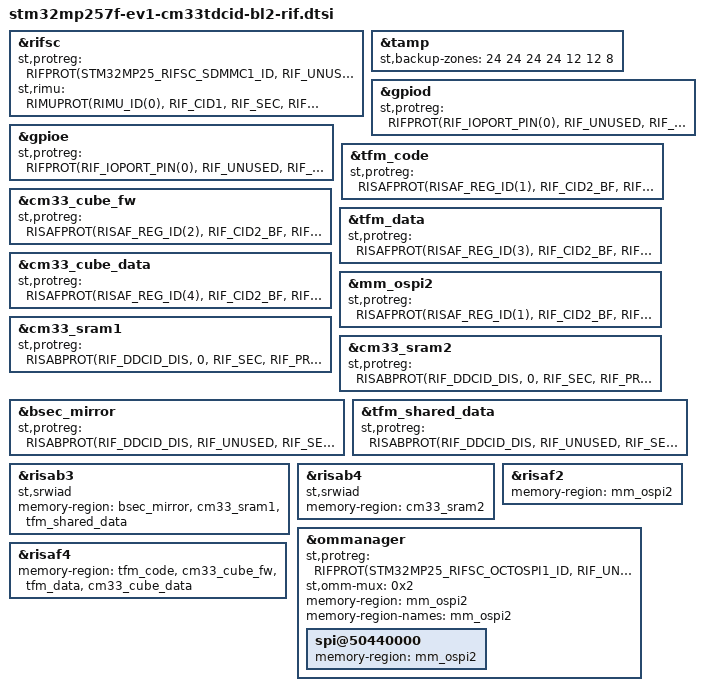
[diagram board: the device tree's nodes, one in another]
// SPDX-License-Identifier: (BSD-3-Clause)
/*
 * Copyright (C) STMicroelectronics 2023 - All Rights Reserved
 */
#include <dt-bindings/rif/stm32mp25-rif.h>
#include <dt-bindings/rif/stm32mp25-rifsc.h>
#include <dt-bindings/rif/stm32mp25-risaf.h>
#include <dt-bindings/rif/stm32mp25-risab.h>

&rifsc {
	status = "okay";

	st,protreg = <
		RIFPROT(STM32MP25_RIFSC_SDMMC1_ID, RIF_UNUSED, RIF_UNLOCK, RIF_SEC, RIF_PRIV, RIF_CID2, RIF_SEM_DIS, RIF_CFEN)
		RIFPROT(STM32MP25_RIFSC_SDMMC2_ID, RIF_UNUSED, RIF_UNLOCK, RIF_SEC, RIF_PRIV, RIF_CID2, RIF_SEM_DIS, RIF_CFEN)
	>;
	st,rimu = <
		RIMUPROT(RIMU_ID(0), RIF_CID1, RIF_SEC, RIF_PRIV, RIF_CIDSEL_P)
		RIMUPROT(RIMU_ID(1), RIF_UNUSED, RIF_SEC, RIF_PRIV, RIF_CIDSEL_P)
		RIMUPROT(RIMU_ID(2), RIF_UNUSED, RIF_SEC, RIF_PRIV, RIF_CIDSEL_P)
		RIMUPROT(RIMU_ID(3), RIF_CID0, RIF_NSEC, RIF_NPRIV, RIF_CIDSEL_P)
		RIMUPROT(RIMU_ID(4), RIF_CID0, RIF_NSEC, RIF_NPRIV, RIF_CIDSEL_P)
		RIMUPROT(RIMU_ID(5), RIF_CID0, RIF_NSEC, RIF_NPRIV, RIF_CIDSEL_P)
		RIMUPROT(RIMU_ID(6), RIF_CID0, RIF_NSEC, RIF_NPRIV, RIF_CIDSEL_P)
		RIMUPROT(RIMU_ID(7), RIF_CID0, RIF_NSEC, RIF_NPRIV, RIF_CIDSEL_P)
		RIMUPROT(RIMU_ID(8), RIF_CID1, RIF_NSEC, RIF_NPRIV, RIF_CIDSEL_P)
		RIMUPROT(RIMU_ID(9), RIF_CID1, RIF_NSEC, RIF_NPRIV, RIF_CIDSEL_P)
		RIMUPROT(RIMU_ID(10), RIF_CID0, RIF_NSEC, RIF_NPRIV, RIF_CIDSEL_P)
		RIMUPROT(RIMU_ID(11), RIF_CID0, RIF_NSEC, RIF_NPRIV, RIF_CIDSEL_M)
		RIMUPROT(RIMU_ID(12), RIF_CID0, RIF_NSEC, RIF_NPRIV, RIF_CIDSEL_M)
		RIMUPROT(RIMU_ID(13), RIF_CID0, RIF_NSEC, RIF_NPRIV, RIF_CIDSEL_M)
		RIMUPROT(RIMU_ID(14), RIF_CID0, RIF_NSEC, RIF_NPRIV, RIF_CIDSEL_P)
		RIMUPROT(RIMU_ID(15), RIF_CID0, RIF_NSEC, RIF_NPRIV, RIF_CIDSEL_P)
	>;
};

&tamp {
	st,backup-zones = <24 24 24 24 12 12 8>;
};

&gpiod {
	st,protreg = <
		RIFPROT(RIF_IOPORT_PIN(0), RIF_UNUSED, RIF_UNLOCK, RIF_SEC, RIF_PRIV, RIF_CID2, RIF_SEM_DIS, RIF_CFEN)
		RIFPROT(RIF_IOPORT_PIN(1), RIF_UNUSED, RIF_UNLOCK, RIF_SEC, RIF_NPRIV, RIF_CID1, RIF_SEM_DIS, RIF_CFEN)
		RIFPROT(RIF_IOPORT_PIN(2), RIF_UNUSED, RIF_UNLOCK, RIF_SEC, RIF_PRIV, RIF_CID1, RIF_SEM_DIS, RIF_CFEN)
		RIFPROT(RIF_IOPORT_PIN(3), RIF_UNUSED, RIF_UNLOCK, RIF_SEC, RIF_PRIV, RIF_CID2, RIF_SEM_DIS, RIF_CFEN)
		RIFPROT(RIF_IOPORT_PIN(4), RIF_UNUSED, RIF_UNLOCK, RIF_SEC, RIF_PRIV, RIF_CID2, RIF_SEM_DIS, RIF_CFEN)
		RIFPROT(RIF_IOPORT_PIN(5), RIF_UNUSED, RIF_UNLOCK, RIF_SEC, RIF_PRIV, RIF_CID2, RIF_SEM_DIS, RIF_CFEN)
		RIFPROT(RIF_IOPORT_PIN(6), RIF_UNUSED, RIF_UNLOCK, RIF_SEC, RIF_PRIV, RIF_CID2, RIF_SEM_DIS, RIF_CFEN)
		RIFPROT(RIF_IOPORT_PIN(7), RIF_UNUSED, RIF_UNLOCK, RIF_SEC, RIF_PRIV, RIF_CID2, RIF_SEM_DIS, RIF_CFEN)
		RIFPROT(RIF_IOPORT_PIN(8), RIF_UNUSED, RIF_UNLOCK, RIF_SEC, RIF_PRIV, RIF_CID1, RIF_SEM_DIS, RIF_CFEN)
		RIFPROT(RIF_IOPORT_PIN(9), RIF_UNUSED, RIF_UNLOCK, RIF_SEC, RIF_PRIV, RIF_CID1, RIF_SEM_DIS, RIF_CFEN)
		RIFPROT(RIF_IOPORT_PIN(10), RIF_UNUSED, RIF_UNLOCK, RIF_SEC, RIF_NPRIV, RIF_CID1, RIF_SEM_DIS, RIF_CFEN)
		RIFPROT(RIF_IOPORT_PIN(11), RIF_UNUSED, RIF_UNLOCK, RIF_SEC, RIF_NPRIV, RIF_CID1, RIF_SEM_DIS, RIF_CFEN)
		RIFPROT(RIF_IOPORT_PIN(12), RIF_UNUSED, RIF_UNLOCK, RIF_NSEC, RIF_NPRIV, RIF_UNUSED, RIF_SEM_DIS, RIF_CFDIS)
		RIFPROT(RIF_IOPORT_PIN(13), RIF_UNUSED, RIF_UNLOCK, RIF_NSEC, RIF_NPRIV, RIF_UNUSED, RIF_SEM_DIS, RIF_CFDIS)
		RIFPROT(RIF_IOPORT_PIN(14), RIF_UNUSED, RIF_UNLOCK, RIF_NSEC, RIF_NPRIV, RIF_UNUSED, RIF_SEM_DIS, RIF_CFDIS)
		RIFPROT(RIF_IOPORT_PIN(15), RIF_UNUSED, RIF_UNLOCK, RIF_NSEC, RIF_NPRIV, RIF_UNUSED, RIF_SEM_DIS, RIF_CFDIS)
	>;
};

&gpioe {
	st,protreg = <
		RIFPROT(RIF_IOPORT_PIN(0), RIF_UNUSED, RIF_UNLOCK, RIF_SEC, RIF_PRIV, RIF_CID2, RIF_SEM_DIS, RIF_CFEN)
		RIFPROT(RIF_IOPORT_PIN(1), RIF_UNUSED, RIF_UNLOCK, RIF_SEC, RIF_PRIV, RIF_CID2, RIF_SEM_DIS, RIF_CFEN)
		RIFPROT(RIF_IOPORT_PIN(2), RIF_UNUSED, RIF_UNLOCK, RIF_SEC, RIF_PRIV, RIF_CID2, RIF_SEM_DIS, RIF_CFEN)
		RIFPROT(RIF_IOPORT_PIN(3), RIF_UNUSED, RIF_UNLOCK, RIF_SEC, RIF_PRIV, RIF_CID2, RIF_SEM_DIS, RIF_CFEN)
		RIFPROT(RIF_IOPORT_PIN(4), RIF_UNUSED, RIF_UNLOCK, RIF_SEC, RIF_PRIV, RIF_CID2, RIF_SEM_DIS, RIF_CFEN)
		RIFPROT(RIF_IOPORT_PIN(5), RIF_UNUSED, RIF_UNLOCK, RIF_SEC, RIF_PRIV, RIF_CID2, RIF_SEM_DIS, RIF_CFEN)
		RIFPROT(RIF_IOPORT_PIN(6), RIF_UNUSED, RIF_UNLOCK, RIF_SEC, RIF_PRIV, RIF_CID2, RIF_SEM_DIS, RIF_CFEN)
		RIFPROT(RIF_IOPORT_PIN(7), RIF_UNUSED, RIF_UNLOCK, RIF_SEC, RIF_PRIV, RIF_CID2, RIF_SEM_DIS, RIF_CFEN)
		RIFPROT(RIF_IOPORT_PIN(8), RIF_UNUSED, RIF_UNLOCK, RIF_SEC, RIF_PRIV, RIF_CID2, RIF_SEM_DIS, RIF_CFEN)
		RIFPROT(RIF_IOPORT_PIN(9), RIF_UNUSED, RIF_UNLOCK, RIF_SEC, RIF_PRIV, RIF_CID2, RIF_SEM_DIS, RIF_CFEN)
		RIFPROT(RIF_IOPORT_PIN(10), RIF_UNUSED, RIF_UNLOCK, RIF_SEC, RIF_PRIV, RIF_CID2, RIF_SEM_DIS, RIF_CFEN)
		RIFPROT(RIF_IOPORT_PIN(11), RIF_UNUSED, RIF_UNLOCK, RIF_SEC, RIF_PRIV, RIF_CID2, RIF_SEM_DIS, RIF_CFEN)
		RIFPROT(RIF_IOPORT_PIN(12), RIF_UNUSED, RIF_UNLOCK, RIF_SEC, RIF_PRIV, RIF_CID2, RIF_SEM_DIS, RIF_CFEN)
		RIFPROT(RIF_IOPORT_PIN(13), RIF_UNUSED, RIF_UNLOCK, RIF_SEC, RIF_PRIV, RIF_CID2, RIF_SEM_DIS, RIF_CFEN)
		RIFPROT(RIF_IOPORT_PIN(14), RIF_UNUSED, RIF_UNLOCK, RIF_SEC, RIF_PRIV, RIF_CID2, RIF_SEM_DIS, RIF_CFEN)
		RIFPROT(RIF_IOPORT_PIN(15), RIF_UNUSED, RIF_UNLOCK, RIF_SEC, RIF_PRIV, RIF_CID2, RIF_SEM_DIS, RIF_CFEN)
	>;
};

&tfm_code {
	st,protreg = <RISAFPROT(RISAF_REG_ID(1), RIF_CID2_BF, RIF_CID2_BF, 0, RIF_SEC, RIF_ENC_EN, RIF_BREN_EN)>;
};

&cm33_cube_fw {
	st,protreg = <RISAFPROT(RISAF_REG_ID(2), RIF_CID2_BF, RIF_CID2_BF, 0, RIF_SEC, RIF_ENC_DIS, RIF_BREN_EN)>;
};

&tfm_data {
	st,protreg = <RISAFPROT(RISAF_REG_ID(3), RIF_CID2_BF, RIF_CID2_BF, 0, RIF_SEC, RIF_ENC_EN, RIF_BREN_EN)>;
};

&cm33_cube_data {
	st,protreg = <RISAFPROT(RISAF_REG_ID(4), RIF_CID2_BF, RIF_CID2_BF, 0, RIF_SEC, RIF_ENC_DIS, RIF_BREN_EN)>;
};

&mm_ospi2 {
	st,protreg = <RISAFPROT(RISAF_REG_ID(1), RIF_CID2_BF, RIF_CID2_BF, 0, RIF_SEC, RIF_ENC_DIS, RIF_BREN_EN)>;
};

&cm33_sram1 {
	st,protreg = <RISABPROT(RIF_DDCID_DIS, 0, RIF_SEC, RIF_PRIV, RIF_CFDIS, 0, 0, 0)>;
};

&cm33_sram2 {
	st,protreg = <RISABPROT(RIF_DDCID_DIS, 0, RIF_SEC, RIF_PRIV, RIF_CFDIS, 0, 0, 0)>;
};

&bsec_mirror {
	st,protreg = <RISABPROT(RIF_DDCID_DIS, RIF_UNUSED, RIF_SEC, RIF_UNUSED, RIF_CFEN, RIF_CID1_BF|RIF_CID2_BF, RIF_CID2_BF, RIF_CID1_BF|RIF_CID2_BF)>;
};

&tfm_shared_data {
	st,protreg = <RISABPROT(RIF_DDCID_DIS, RIF_UNUSED, RIF_SEC, RIF_UNUSED, RIF_CFEN, RIF_CID2_BF, RIF_CID2_BF, RIF_CID2_BF)>;
};

&risab3 {
	st,srwiad;
	memory-region = <&bsec_mirror>, <&cm33_sram1>, <&tfm_shared_data>;
	status = "okay";
};

&risab4 {
	st,srwiad;
	memory-region = <&cm33_sram2>;
	status = "okay";
};

&risaf2 {
	memory-region= <&mm_ospi2>;
	status = "okay";
};

&ommanager {
	st,protreg = <
		RIFPROT(STM32MP25_RIFSC_OCTOSPI1_ID, RIF_UNUSED, RIF_UNLOCK, RIF_SEC, RIF_PRIV, RIF_CID2, RIF_SEM_DIS, RIF_CFEN)
		RIFPROT(STM32MP25_RIFSC_OCTOSPI2_ID, RIF_UNUSED, RIF_UNLOCK, RIF_SEC, RIF_PRIV, RIF_CID2, RIF_SEM_DIS, RIF_CFEN)
		RIFPROT(STM32MP25_RIFSC_OCTOSPIM_ID, RIF_UNUSED, RIF_UNLOCK, RIF_SEC, RIF_PRIV, RIF_CID2, RIF_SEM_DIS, RIF_CFEN)
		RIFPROT(STM32MP25_RIFSC_OTFDEC1_ID, RIF_UNUSED, RIF_UNLOCK, RIF_SEC, RIF_PRIV, RIF_CID2, RIF_SEM_DIS, RIF_CFEN)
		RIFPROT(STM32MP25_RIFSC_OTFDEC2_ID, RIF_UNUSED, RIF_UNLOCK, RIF_SEC, RIF_PRIV, RIF_CID2, RIF_SEM_DIS, RIF_CFEN)
	>;

	st,omm-mux = <0x2>;
	memory-region = <&mm_ospi2>;
	memory-region-names = "mm_ospi2";

	spi@50440000 {
		memory-region = <&mm_ospi2>;
	};
};

&risaf4 {
	memory-region = <&tfm_code>, <&cm33_cube_fw>, <&tfm_data>, <&cm33_cube_data>;
	status = "okay";
};
